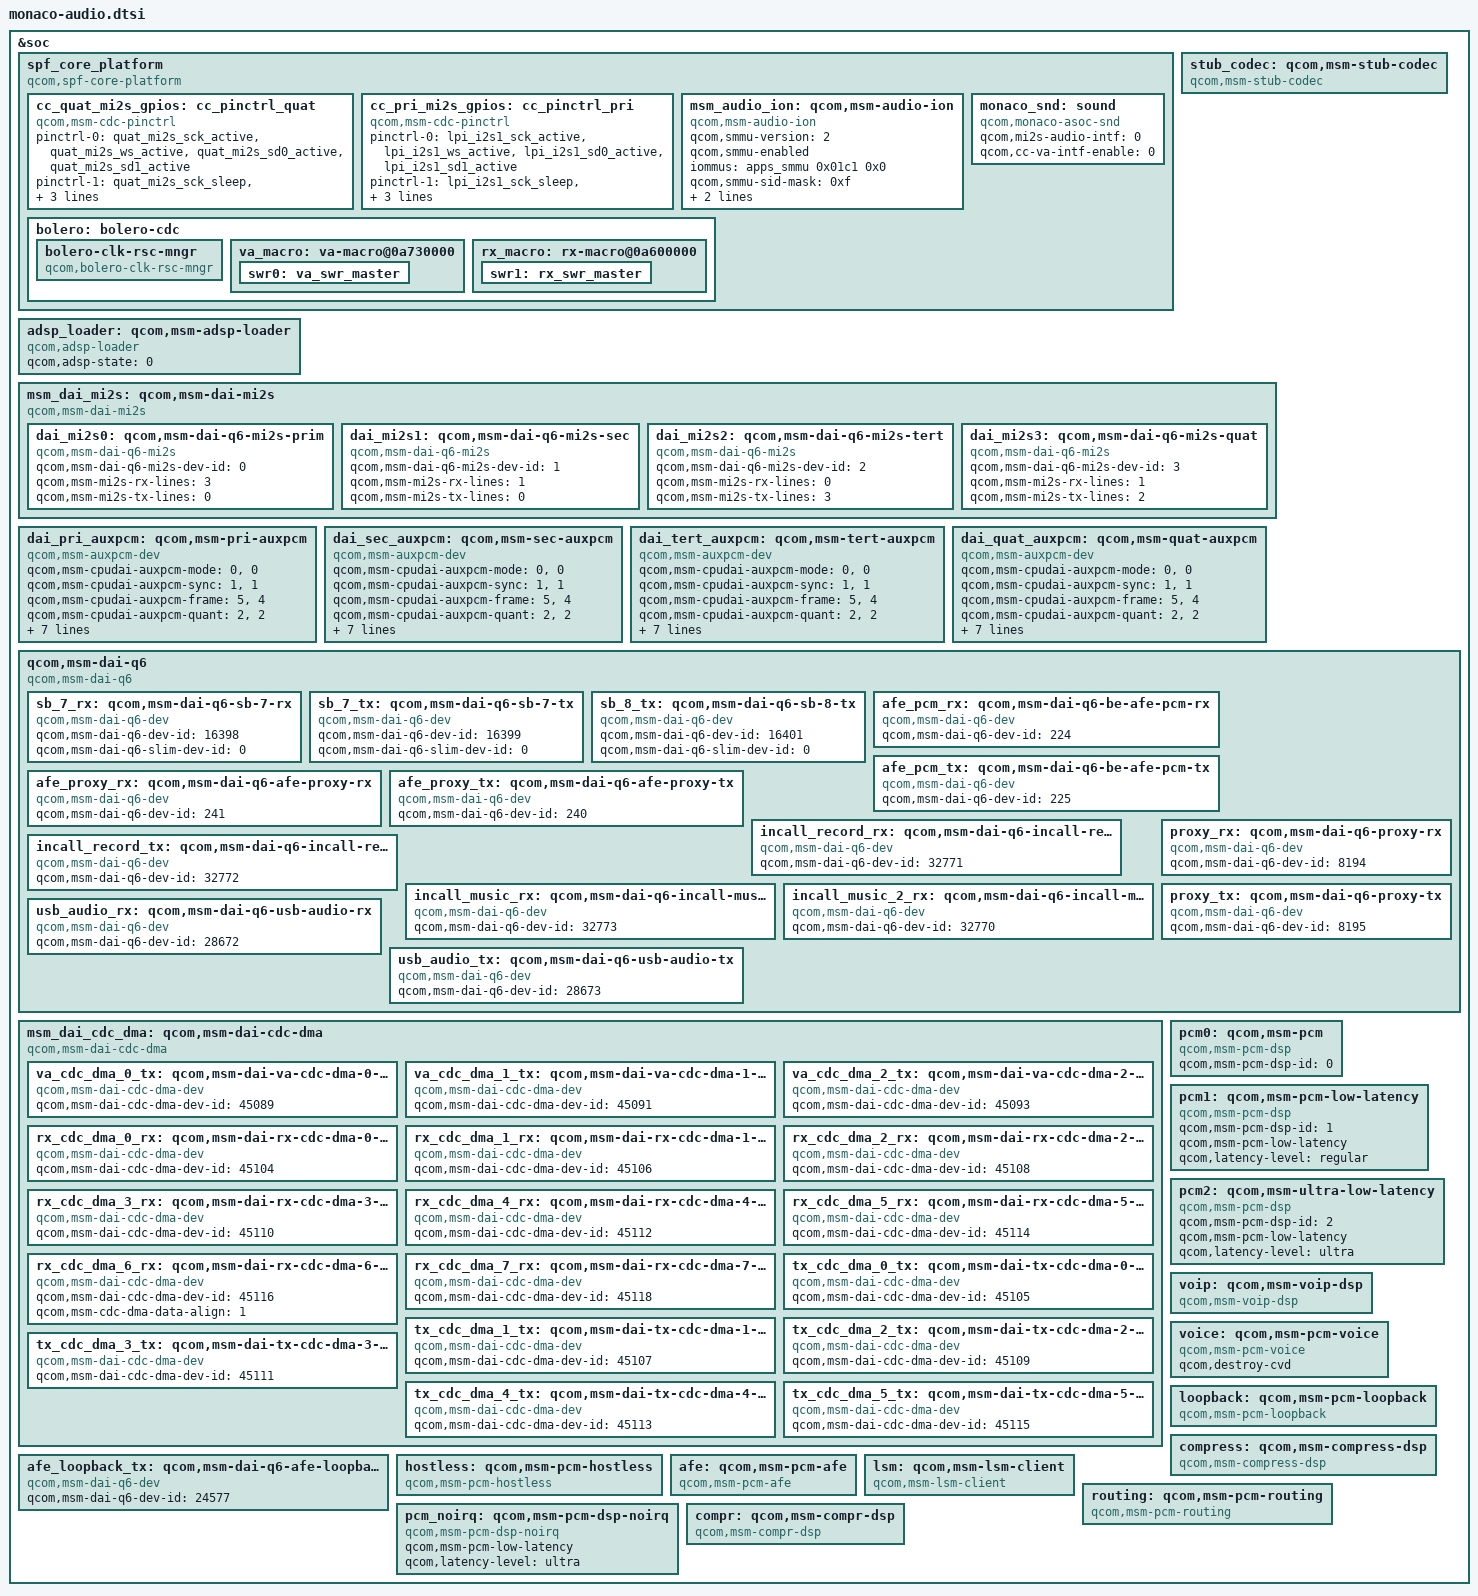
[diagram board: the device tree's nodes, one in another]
#include <dt-bindings/clock/qcom,audio-ext-clk.h>

&soc {
	spf_core_platform: spf_core_platform {
		compatible = "qcom,spf-core-platform";
	};

	adsp_loader: qcom,msm-adsp-loader {
		status = "ok";
		compatible = "qcom,adsp-loader";
		qcom,adsp-state = <0>;
	};

	stub_codec: qcom,msm-stub-codec {
		compatible = "qcom,msm-stub-codec";
	};

	msm_dai_mi2s: qcom,msm-dai-mi2s {
		compatible = "qcom,msm-dai-mi2s";
		dai_mi2s0: qcom,msm-dai-q6-mi2s-prim {
			compatible = "qcom,msm-dai-q6-mi2s";
			qcom,msm-dai-q6-mi2s-dev-id = <0>;
			qcom,msm-mi2s-rx-lines = <3>;
			qcom,msm-mi2s-tx-lines = <0>;
		};

		dai_mi2s1: qcom,msm-dai-q6-mi2s-sec {
			compatible = "qcom,msm-dai-q6-mi2s";
			qcom,msm-dai-q6-mi2s-dev-id = <1>;
			qcom,msm-mi2s-rx-lines = <1>;
			qcom,msm-mi2s-tx-lines = <0>;
		};

		dai_mi2s2: qcom,msm-dai-q6-mi2s-tert {
			compatible = "qcom,msm-dai-q6-mi2s";
			qcom,msm-dai-q6-mi2s-dev-id = <2>;
			qcom,msm-mi2s-rx-lines = <0>;
			qcom,msm-mi2s-tx-lines = <3>;
		};

		dai_mi2s3: qcom,msm-dai-q6-mi2s-quat {
			compatible = "qcom,msm-dai-q6-mi2s";
			qcom,msm-dai-q6-mi2s-dev-id = <3>;
			qcom,msm-mi2s-rx-lines = <1>;
			qcom,msm-mi2s-tx-lines = <2>;
		};
	};

	dai_pri_auxpcm: qcom,msm-pri-auxpcm {
		compatible = "qcom,msm-auxpcm-dev";
		qcom,msm-cpudai-auxpcm-mode = <0>, <0>;
		qcom,msm-cpudai-auxpcm-sync = <1>, <1>;
		qcom,msm-cpudai-auxpcm-frame = <5>, <4>;
		qcom,msm-cpudai-auxpcm-quant = <2>, <2>;
		qcom,msm-cpudai-auxpcm-num-slots = <1>, <1>;
		qcom,msm-cpudai-auxpcm-slot-mapping = <1>, <1>;
		qcom,msm-cpudai-auxpcm-data = <0>, <0>;
		qcom,msm-cpudai-auxpcm-pcm-clk-rate = <2048000>, <2048000>;
		qcom,msm-auxpcm-interface = "primary";
		qcom,msm-cpudai-afe-clk-ver = <2>;
	};

	dai_sec_auxpcm: qcom,msm-sec-auxpcm {
		compatible = "qcom,msm-auxpcm-dev";
		qcom,msm-cpudai-auxpcm-mode = <0>, <0>;
		qcom,msm-cpudai-auxpcm-sync = <1>, <1>;
		qcom,msm-cpudai-auxpcm-frame = <5>, <4>;
		qcom,msm-cpudai-auxpcm-quant = <2>, <2>;
		qcom,msm-cpudai-auxpcm-num-slots = <1>, <1>;
		qcom,msm-cpudai-auxpcm-slot-mapping = <1>, <1>;
		qcom,msm-cpudai-auxpcm-data = <0>, <0>;
		qcom,msm-cpudai-auxpcm-pcm-clk-rate = <2048000>, <2048000>;
		qcom,msm-auxpcm-interface = "secondary";
		qcom,msm-cpudai-afe-clk-ver = <2>;
	};

	dai_tert_auxpcm: qcom,msm-tert-auxpcm {
		compatible = "qcom,msm-auxpcm-dev";
		qcom,msm-cpudai-auxpcm-mode = <0>, <0>;
		qcom,msm-cpudai-auxpcm-sync = <1>, <1>;
		qcom,msm-cpudai-auxpcm-frame = <5>, <4>;
		qcom,msm-cpudai-auxpcm-quant = <2>, <2>;
		qcom,msm-cpudai-auxpcm-num-slots = <1>, <1>;
		qcom,msm-cpudai-auxpcm-slot-mapping = <1>, <1>;
		qcom,msm-cpudai-auxpcm-data = <0>, <0>;
		qcom,msm-cpudai-auxpcm-pcm-clk-rate = <2048000>, <2048000>;
		qcom,msm-auxpcm-interface = "tertiary";
		qcom,msm-cpudai-afe-clk-ver = <2>;
	};

	dai_quat_auxpcm: qcom,msm-quat-auxpcm {
		compatible = "qcom,msm-auxpcm-dev";
		qcom,msm-cpudai-auxpcm-mode = <0>, <0>;
		qcom,msm-cpudai-auxpcm-sync = <1>, <1>;
		qcom,msm-cpudai-auxpcm-frame = <5>, <4>;
		qcom,msm-cpudai-auxpcm-quant = <2>, <2>;
		qcom,msm-cpudai-auxpcm-num-slots = <1>, <1>;
		qcom,msm-cpudai-auxpcm-slot-mapping = <1>, <1>;
		qcom,msm-cpudai-auxpcm-data = <0>, <0>;
		qcom,msm-cpudai-auxpcm-pcm-clk-rate = <2048000>, <2048000>;
		qcom,msm-auxpcm-interface = "quaternary";
		qcom,msm-cpudai-afe-clk-ver = <2>;
	};

	qcom,msm-dai-q6 {
		compatible = "qcom,msm-dai-q6";
		sb_7_rx: qcom,msm-dai-q6-sb-7-rx {
			compatible = "qcom,msm-dai-q6-dev";
			qcom,msm-dai-q6-dev-id = <16398>;
			qcom,msm-dai-q6-slim-dev-id = <0>;
		};

		sb_7_tx: qcom,msm-dai-q6-sb-7-tx {
			compatible = "qcom,msm-dai-q6-dev";
			qcom,msm-dai-q6-dev-id = <16399>;
			qcom,msm-dai-q6-slim-dev-id = <0>;
		};

		sb_8_tx: qcom,msm-dai-q6-sb-8-tx {
			compatible = "qcom,msm-dai-q6-dev";
			qcom,msm-dai-q6-dev-id = <16401>;
			qcom,msm-dai-q6-slim-dev-id = <0>;
		};

		afe_pcm_rx: qcom,msm-dai-q6-be-afe-pcm-rx {
			compatible = "qcom,msm-dai-q6-dev";
			qcom,msm-dai-q6-dev-id = <224>;
		};

		afe_pcm_tx: qcom,msm-dai-q6-be-afe-pcm-tx {
			compatible = "qcom,msm-dai-q6-dev";
			qcom,msm-dai-q6-dev-id = <225>;
		};

		afe_proxy_rx: qcom,msm-dai-q6-afe-proxy-rx {
			compatible = "qcom,msm-dai-q6-dev";
			qcom,msm-dai-q6-dev-id = <241>;
		};

		afe_proxy_tx: qcom,msm-dai-q6-afe-proxy-tx {
			compatible = "qcom,msm-dai-q6-dev";
			qcom,msm-dai-q6-dev-id = <240>;
		};

		incall_record_rx: qcom,msm-dai-q6-incall-record-rx {
			compatible = "qcom,msm-dai-q6-dev";
			qcom,msm-dai-q6-dev-id = <32771>;
		};

		incall_record_tx: qcom,msm-dai-q6-incall-record-tx {
			compatible = "qcom,msm-dai-q6-dev";
			qcom,msm-dai-q6-dev-id = <32772>;
		};

		incall_music_rx: qcom,msm-dai-q6-incall-music-rx {
			compatible = "qcom,msm-dai-q6-dev";
			qcom,msm-dai-q6-dev-id = <32773>;
		};

		incall_music_2_rx: qcom,msm-dai-q6-incall-music-2-rx {
			compatible = "qcom,msm-dai-q6-dev";
			qcom,msm-dai-q6-dev-id = <32770>;
		};

		proxy_rx: qcom,msm-dai-q6-proxy-rx {
			compatible = "qcom,msm-dai-q6-dev";
			qcom,msm-dai-q6-dev-id = <8194>;
		};

		proxy_tx: qcom,msm-dai-q6-proxy-tx {
			compatible = "qcom,msm-dai-q6-dev";
			qcom,msm-dai-q6-dev-id = <8195>;
		};

		usb_audio_rx: qcom,msm-dai-q6-usb-audio-rx {
			compatible = "qcom,msm-dai-q6-dev";
			qcom,msm-dai-q6-dev-id = <28672>;
		};

		usb_audio_tx: qcom,msm-dai-q6-usb-audio-tx {
			compatible = "qcom,msm-dai-q6-dev";
			qcom,msm-dai-q6-dev-id = <28673>;
		};
	};

	msm_dai_cdc_dma: qcom,msm-dai-cdc-dma {
		compatible = "qcom,msm-dai-cdc-dma";

		va_cdc_dma_0_tx: qcom,msm-dai-va-cdc-dma-0-tx {
			compatible = "qcom,msm-dai-cdc-dma-dev";
			qcom,msm-dai-cdc-dma-dev-id = <45089>;
		};

		va_cdc_dma_1_tx: qcom,msm-dai-va-cdc-dma-1-tx {
			compatible = "qcom,msm-dai-cdc-dma-dev";
			qcom,msm-dai-cdc-dma-dev-id = <45091>;
		};

		va_cdc_dma_2_tx: qcom,msm-dai-va-cdc-dma-2-tx {
			compatible = "qcom,msm-dai-cdc-dma-dev";
			qcom,msm-dai-cdc-dma-dev-id = <45093>;
		};

		rx_cdc_dma_0_rx: qcom,msm-dai-rx-cdc-dma-0-rx {
			compatible = "qcom,msm-dai-cdc-dma-dev";
			qcom,msm-dai-cdc-dma-dev-id = <45104>;
		};

		rx_cdc_dma_1_rx: qcom,msm-dai-rx-cdc-dma-1-rx {
			compatible = "qcom,msm-dai-cdc-dma-dev";
			qcom,msm-dai-cdc-dma-dev-id = <45106>;
		};

		rx_cdc_dma_2_rx: qcom,msm-dai-rx-cdc-dma-2-rx {
			compatible = "qcom,msm-dai-cdc-dma-dev";
			qcom,msm-dai-cdc-dma-dev-id = <45108>;
		};

		rx_cdc_dma_3_rx: qcom,msm-dai-rx-cdc-dma-3-rx {
			compatible = "qcom,msm-dai-cdc-dma-dev";
			qcom,msm-dai-cdc-dma-dev-id = <45110>;
		};

		rx_cdc_dma_4_rx: qcom,msm-dai-rx-cdc-dma-4-rx {
			compatible = "qcom,msm-dai-cdc-dma-dev";
			qcom,msm-dai-cdc-dma-dev-id = <45112>;
		};

		rx_cdc_dma_5_rx: qcom,msm-dai-rx-cdc-dma-5-rx {
			compatible = "qcom,msm-dai-cdc-dma-dev";
			qcom,msm-dai-cdc-dma-dev-id = <45114>;
		};

		rx_cdc_dma_6_rx: qcom,msm-dai-rx-cdc-dma-6-rx {
			compatible = "qcom,msm-dai-cdc-dma-dev";
			qcom,msm-dai-cdc-dma-dev-id = <45116>;
			qcom,msm-cdc-dma-data-align = <1>;
		};

		rx_cdc_dma_7_rx: qcom,msm-dai-rx-cdc-dma-7-rx {
			compatible = "qcom,msm-dai-cdc-dma-dev";
			qcom,msm-dai-cdc-dma-dev-id = <45118>;
		};

		tx_cdc_dma_0_tx: qcom,msm-dai-tx-cdc-dma-0-tx {
			compatible = "qcom,msm-dai-cdc-dma-dev";
			qcom,msm-dai-cdc-dma-dev-id = <45105>;
		};

		tx_cdc_dma_1_tx: qcom,msm-dai-tx-cdc-dma-1-tx {
			compatible = "qcom,msm-dai-cdc-dma-dev";
			qcom,msm-dai-cdc-dma-dev-id = <45107>;
		};

		tx_cdc_dma_2_tx: qcom,msm-dai-tx-cdc-dma-2-tx {
			compatible = "qcom,msm-dai-cdc-dma-dev";
			qcom,msm-dai-cdc-dma-dev-id = <45109>;
		};

		tx_cdc_dma_3_tx: qcom,msm-dai-tx-cdc-dma-3-tx {
			compatible = "qcom,msm-dai-cdc-dma-dev";
			qcom,msm-dai-cdc-dma-dev-id = <45111>;
		};

		tx_cdc_dma_4_tx: qcom,msm-dai-tx-cdc-dma-4-tx {
			compatible = "qcom,msm-dai-cdc-dma-dev";
			qcom,msm-dai-cdc-dma-dev-id = <45113>;
		};

		tx_cdc_dma_5_tx: qcom,msm-dai-tx-cdc-dma-5-tx {
			compatible = "qcom,msm-dai-cdc-dma-dev";
			qcom,msm-dai-cdc-dma-dev-id = <45115>;
		};
	};

	afe_loopback_tx: qcom,msm-dai-q6-afe-loopback-tx {
		compatible = "qcom,msm-dai-q6-dev";
		qcom,msm-dai-q6-dev-id = <24577>;
	};

	pcm0: qcom,msm-pcm {
		compatible = "qcom,msm-pcm-dsp";
		qcom,msm-pcm-dsp-id = <0>;
	};

	pcm1: qcom,msm-pcm-low-latency {
		compatible = "qcom,msm-pcm-dsp";
		qcom,msm-pcm-dsp-id = <1>;
		qcom,msm-pcm-low-latency;
		qcom,latency-level = "regular";
	};

	pcm2: qcom,msm-ultra-low-latency {
		compatible = "qcom,msm-pcm-dsp";
		qcom,msm-pcm-dsp-id = <2>;
		qcom,msm-pcm-low-latency;
		qcom,latency-level = "ultra";
	};

	voip: qcom,msm-voip-dsp {
		compatible = "qcom,msm-voip-dsp";
	};

	voice: qcom,msm-pcm-voice {
		compatible = "qcom,msm-pcm-voice";
		qcom,destroy-cvd;
	};

	loopback: qcom,msm-pcm-loopback {
		compatible = "qcom,msm-pcm-loopback";
	};

	compress: qcom,msm-compress-dsp {
		compatible = "qcom,msm-compress-dsp";
	};

	hostless: qcom,msm-pcm-hostless {
		compatible = "qcom,msm-pcm-hostless";
	};

	afe: qcom,msm-pcm-afe {
		compatible = "qcom,msm-pcm-afe";
	};

	lsm: qcom,msm-lsm-client {
		compatible = "qcom,msm-lsm-client";
	};

	routing: qcom,msm-pcm-routing {
		compatible = "qcom,msm-pcm-routing";
	};

	pcm_noirq: qcom,msm-pcm-dsp-noirq {
		compatible = "qcom,msm-pcm-dsp-noirq";
		qcom,msm-pcm-low-latency;
		qcom,latency-level = "ultra";
	};

	compr: qcom,msm-compr-dsp {
		compatible = "qcom,msm-compr-dsp";
	};

};

#include "monaco-lpi.dtsi"

&spf_core_platform {
	cc_quat_mi2s_gpios: cc_pinctrl_quat {
		compatible = "qcom,msm-cdc-pinctrl";
		pinctrl-names = "aud_active", "aud_sleep";
		pinctrl-0 = <&quat_mi2s_sck_active &quat_mi2s_ws_active
				&quat_mi2s_sd0_active &quat_mi2s_sd1_active>;

		pinctrl-1 = < &quat_mi2s_sck_sleep &quat_mi2s_ws_sleep
				&quat_mi2s_sd0_sleep &quat_mi2s_sd1_sleep>;
		qcom,lpi-gpios;
	};

	cc_pri_mi2s_gpios: cc_pinctrl_pri {
		compatible = "qcom,msm-cdc-pinctrl";
		pinctrl-names = "aud_active", "aud_sleep";
		pinctrl-0 = <&lpi_i2s1_sck_active &lpi_i2s1_ws_active
				&lpi_i2s1_sd0_active &lpi_i2s1_sd1_active>;

		pinctrl-1 = <&lpi_i2s1_sck_sleep &lpi_i2s1_ws_sleep
				&lpi_i2s1_sd0_sleep &lpi_i2s1_sd1_sleep>;
		qcom,lpi-gpios;
	};

	msm_audio_ion: qcom,msm-audio-ion {
		compatible = "qcom,msm-audio-ion";
		qcom,smmu-version = <2>;
		qcom,smmu-enabled;
		iommus = <&apps_smmu 0x01c1 0x0>;
		qcom,smmu-sid-mask = /bits/ 64 <0xf>;
		qcom,iommu-dma-addr-pool = <0x10000000 0x10000000>;
	};

	monaco_snd: sound {
		compatible = "qcom,monaco-asoc-snd";
		qcom,mi2s-audio-intf = <0>;
		qcom,cc-va-intf-enable = <0>;
	};

	bolero: bolero-cdc {
		bolero-clk-rsc-mngr {
			compatible = "qcom,bolero-clk-rsc-mngr";
		};

		va_macro: va-macro@0a730000 {
			swr0: va_swr_master {
			};
		};

		rx_macro: rx-macro@0a600000 {
			swr1: rx_swr_master {
			};
		};
	};
};
